# S1C31D01 register map
Vendor: Epson; Series: S1C31D01; File version: 1.00
CPU: CM0PLUS r0p1, little endian, MPU, no FPU, VTOR, 2 interrupt priority bits
Registers are 16-bit, read-write, reset 0x0 unless marked. A register's access mark holds for its fields unless they carry their own. Offsets are from the block's base; [hi:lo] are bit positions.

## TSRVR_0 — Temparature sensor control
Base 0x400007C0
0x00 TCTL — Temparature sensor control register
  [0] TEMPEN — Sensor eneble
0x02 VCTL — Reference voltage generator control register
  [1:0] VREFAMD — VREF mode select

## USBMISC — USB miscellaneous configuration register
Base 0x40000970
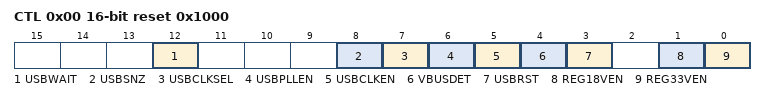
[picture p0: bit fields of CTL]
0x00 CTL reset 0x1000 — Misc Control Register
  [12] USBWAIT
    0=NOWAIT; 1=WAIT
  [8] USBSNZ — USB snooze control enable
    0=DISABLE; 1=ENABLE
  [7] USBCLKSEL — USB clock source select
    0=PLL; 1=USBOSC
  [6] USBPLLEN — PLL operation enable
    0=DISABLE; 1=ENABLE
  [5] USBCLKEN — USB logic circuits clock supply enable
    0=DISABLE; 1=ENABLE
  [4] VBUSDET — USB controller communication enable after VBUS is detected
    0=DISABLE; 1=ENABLE
  [3] USBRST — Reset state control
    0=RESET (Puts USB logic circuits into RESET state); 1=RELEASE (Release USB logic circuits from RESET state)
  [1] REG18VEN — 1.8 V regulator enable for the USB logic circuits
    0=DISABLE; 1=ENABLE
  [0] REG33VEN — 3.3 V regulator enable for the PHY part
    0=DISABLE; 1=ENABLE
0x04 WRDMAEN — USB FIFO Write DMA Request Enable Register
  [3:0] WRDMAEN
0x06 RDDMAEN — USB FIFO Read DMA Request Enable Register
  [3:0] RDDMAEN — USB FIFO DMA ch0 request enable

## QSPI_0 — Quad Synchronous Serial Interface channel 0
Base 0x40000690
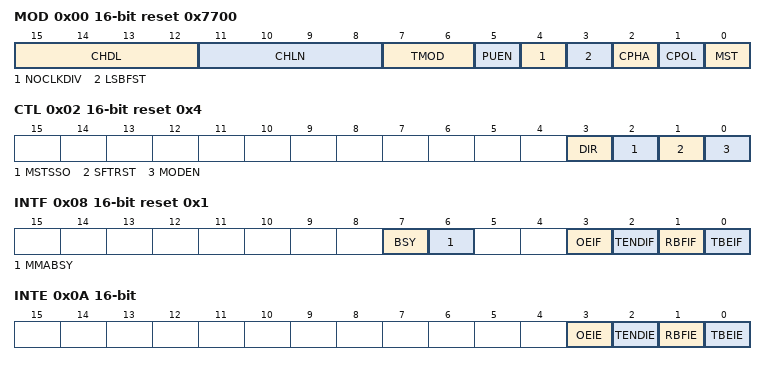
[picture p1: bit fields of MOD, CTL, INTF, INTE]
0x00 MOD reset 0x7700 — QSPI Mode Register
  [15:12] CHDL — These bits determines the number of clocks the serial output data lines will be driven
  [11:8] CHLN — These bits set the number of clocks for data transfer
  [7:6] TMOD — These bits selects the transfer mode
  [5] PUEN — Enable/Disable pull-up/down
  [4] NOCLKDIV — This bit selects QSPICLKn
  [3] LSBFST — This bit configures the data format
  [2] CPHA — This bit sets the QSPI clock phase
  [1] CPOL — This bit sets the QSPI clock polarity
  [0] MST — This bit sets the QSPI operating mode
0x02 CTL reset 0x4 — QSPI Control Register
  [3] DIR — This bit set the transfer direction of SDIO
  [2] MSTSSO — This bit controls the slave select output pin in master mode only
  [1] SFTRST — This bit issues software reset to QSPI
  [0] MODEN — This bit enables the QSPI operations
0x04 TXD — Transmit Data Register
  [15:0] TXD — Transmit data
0x06 RXD ro — Receive Data Register
  [15:0] RXD — Receive data
0x08 INTF reset 0x1 — Interrupt Flag Register
  [7] BSY ro — This bit indicates the QSPI operating status
  [6] MMABSY ro — This bit indicates the QSPI memory mapped access operating status
  [3] OEIF ro — Overrun error interrupt
  [2] TENDIF ro — End-of-transmission interrupt
  [1] RBFIF ro — Receive buffer full interrupt
  [0] TBEIF ro — Transmit buffer empty interrupt
0x0A INTE — QSPI Interrupt Enable Register
  [all] fields
    0=DISABLE; 1=ENABLE
  [3] OEIE — Overrun error interrupt
  [2] TENDIE — End-of-transmission interrupt
  [1] RBFIE — Receive buffer full interrupt
  [0] TBEIE — Transmit buffer empty interrupt
0x0C TBEDMAEN — TBE DMA Enable Register
  [3:0] TBEDMAEN — TBE DMA ch0 request enable
0x0E RBFDMAEN — RBFDMAEN Receive Buffer Full DMA Request Enable Register
  [3:0] RBFDMAEN — RBF DMA request enable
0x10 FRLDMAEN — FRLDMAEN QSPI Fifo Read Level Not Empty DMA Request Enable Register
  [3:0] FRLDMAEN — FRL DMA ch0 request enable
0x12 MMACFG1 — QSPI Memory Mapped Access Configuration Register 1
  [3:0] TCSH — These bits specify the number of clocks for slave select high between non-contiguous address flash memory read
0x14 RMADRH — QSPI Remapping Start Address High Register
  [15:4] RMADR — The most significant bits of register bits will be appended to the input offset address from the system AHB-Lite bus to this QSPI module
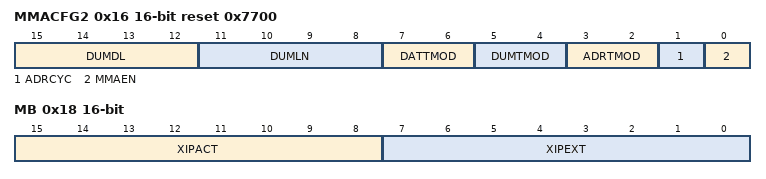
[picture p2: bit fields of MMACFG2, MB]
0x16 MMACFG2 reset 0x7700 — QSPI Memory Mapped Access Configuration Register 2
  [15:12] DUMDL — These bits determines the number of clocks the serial output data lines will be driven for dummy cycle
  [11:8] DUMLN — These bits set the number of clocks for dummy cycle during host memory mapped access to the external flash
  [7:6] DATTMOD — These bits specify the number of clocks for slave select high between non-contiguous address flash memory read
  [5:4] DUMTMOD — These bits selects the transfer mode for dummy cycle during host memory mapped access to the external flash
  [3:2] ADRTMOD — These bits selects the transfer mode for address cycle during host memory mapped access to the external flash
  [1] ADRCYC — This bit selects 24-bit or 32-bit address mode used during host memory mapped access to the external flash
  [0] MMAEN — This bit enables host memory mapped access to the external flash
0x18 MB — QSPI Mode Byte Register
  [15:8] XIPACT — These bit sets the mode byte for activation of XIP access during host memory mapped access to the external flash
  [7:0] XIPEXT — These bit sets the mode byte for exit of XIP access during host memory mapped access to the external flash
